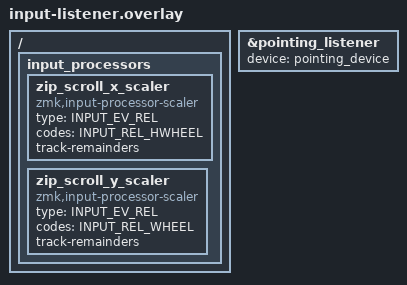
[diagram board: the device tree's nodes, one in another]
#include <input/processors.dtsi>
#include <zephyr/dt-bindings/input/input-event-codes.h>

/ {
    input_processors {
        zip_scroll_x_scaler: zip_scroll_x_scaler {
            compatible = "zmk,input-processor-scaler";
            #input-processor-cells = <2>;
            type = <INPUT_EV_REL>;
            codes = <INPUT_REL_HWHEEL>;
            track-remainders;
        };

        zip_scroll_y_scaler: zip_scroll_y_scaler {
            compatible = "zmk,input-processor-scaler";
            #input-processor-cells = <2>;
            type = <INPUT_EV_REL>;
            codes = <INPUT_REL_WHEEL>;
            track-remainders;
        };
    };
};

&pointing_listener {
    status = "okay";
    device = <&pointing_device>;
};
